VERSION ""

NS_ :

BS_:

BU_: ECU TESTER

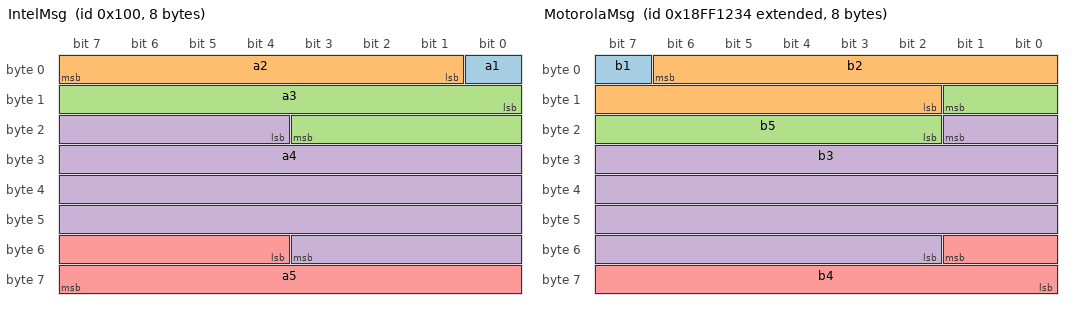
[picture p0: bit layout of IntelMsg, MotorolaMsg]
BO_ 256 IntelMsg: 8 ECU
 SG_ a1 : 0|1@1+ (1,0) [0|1] "" TESTER
 SG_ a2 : 1|7@1- (1,0) [0|0] "" TESTER
 SG_ a3 : 8|12@1+ (0.1,-40) [-40|369.5] "degC" TESTER
 SG_ a4 : 20|32@1- (1,0) [0|0] "" TESTER
 SG_ a5 : 52|12@1+ (-0.5,100) [0|0] "" TESTER

BO_ 2566853172 MotorolaMsg: 8 TESTER
 SG_ b1 : 7|1@0+ (1,0) [0|1] "" ECU
 SG_ b2 : 6|13@0- (0.25,10) [0|0] "" ECU
 SG_ b5 : 9|8@0+ (0.001,0) [0|0.255] "V" ECU
 SG_ b3 : 17|32@0+ (1,0) [0|0] "" ECU
 SG_ b4 : 49|10@0- (5,-3) [-1000|1000] "" ECU

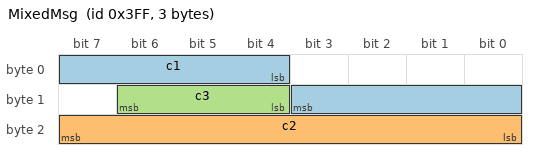
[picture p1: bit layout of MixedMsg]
BO_ 1023 MixedMsg: 3 ECU
 SG_ c1 : 4|8@1+ (3,-7) [0|0] "" TESTER
 SG_ c2 : 23|8@0- (1,0) [-100|100] "" TESTER
 SG_ c3 : 12|3@1+ (1,0) [0|7] "" TESTER

BA_DEF_ BO_  "GenMsgCycleTime" INT 0 65535;
BA_DEF_ BO_  "GenMsgTimeoutTime" INT 0 65535;
BA_DEF_ SG_  "GenSigStartValue" FLOAT -2147483648 4294967295;
BA_DEF_DEF_  "GenMsgCycleTime" 0;
BA_DEF_DEF_  "GenMsgTimeoutTime" 0;
BA_DEF_DEF_  "GenSigStartValue" 0;
BA_ "GenMsgCycleTime" BO_ 256 20;
BA_ "GenMsgCycleTime" BO_ 2566853172 50;
BA_ "GenMsgTimeoutTime" BO_ 2566853172 200;
BA_ "GenSigStartValue" SG_ 256 a3 400;
BA_ "GenSigStartValue" SG_ 2566853172 b4 -3;
